# NUC100DN_v1 register map
File version: 1.0
Registers are 32-bit, read-write, reset 0x0 unless marked. A register's access mark holds for its fields unless they carry their own. Offsets are from the block's base; [hi:lo] are bit positions; lines under a group give offsets from that group; {n}, {i} and the like mark numbered series; 'fields as' and 'values as' point back to an identical list.

## PWMA — PWM Register Map
Base 0x40040000
Same registers: PWMB 0x40140000
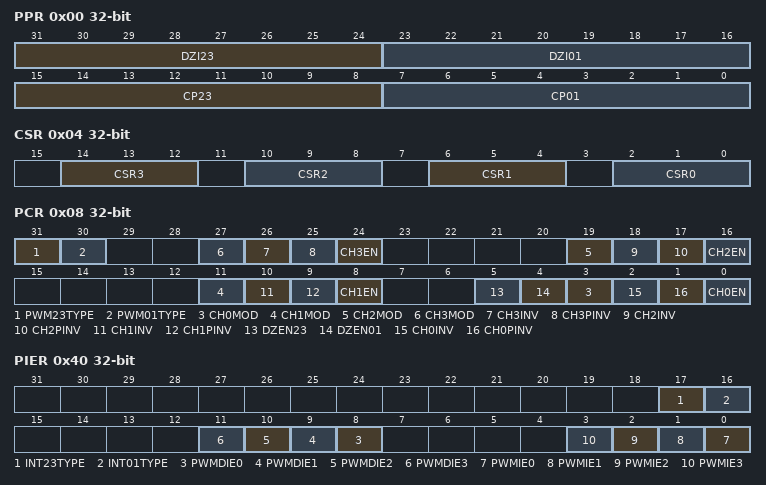
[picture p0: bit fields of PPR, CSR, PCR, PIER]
0x00 PPR — PWM Prescaler Register
  [31:24] DZI23 — Dead-zone Interval for Pair of Channel2 and Channel3 (PWM2 and PWM3 Pair for PWM Group A, PWM6 and PWM7 Pair for PWM Group B). These 8-bit determine the Dead-zone length.
  [23:16] DZI01 — Dead-zone Interval for Pair of Channel 0 and Channel 1 (PWM0 and PWM1 Pair for PWM Group A, PWM4 and PWM5 Pair for PWM Group B). These 8-bit determine the Dead-zone length.
  [15:8] CP23 — Clock Prescaler 2 (PWM-timer2 / 3 for Group a and PWM-timer 6 / 7 for Group B). Clock input is divided by (CP23 + 1) before it is fed to the corresponding PWM-timer
  [7:0] CP01 — Clock Prescaler 0 (PWM-timer 0 / 1 for Group a and PWM-timer 4 / 5 for Group B). Clock input is divided by (CP01 + 1) before it is fed to the corresponding PWM-timer
0x04 CSR — PWM Clock Source Divider Select Register
  [14:12] CSR3 — PWM Timer 3 Clock Source Divider Selection (PWM Timer 3 for Group a and PWM Timer 7 for Group B). Select clock source divider for PWM timer 3.
    0=Input Clock Divided by 2; 1=Input Clock Divided by 4; 2=Input Clock Divided by 8; 3=Input Clock Divided by 16; 4=Input Clock Divided by 1
  [10:8] CSR2 — PWM Timer 2 Clock Source Divider Selection (PWM Timer 2 for Group a and PWM Timer 6 for Group B). Select clock source divider for PWM timer 2. (Table is the same as CSR3)
  [6:4] CSR1 — PWM Timer 1 Clock Source Divider Selection (PWM Timer 1 for Group a and PWM Timer 5 for Group B). Select clock source divider for PWM timer 1. (Table is the same as CSR3)
  [2:0] CSR0 — PWM Timer 0 Clock Source Divider Selection (PWM Timer 0 for Group a and PWM Timer 4 for Group B). Select clock source divider for PWM timer 0. (Table is the same as CSR3)
0x08 PCR — PWM Control Register
  [31] PWM23TYPE — PWM23 Aligned Type Selection Bit (PWM2 and PWM3 Pair for PWM Group A, PWM6 and PWM7 Pair for PWM Group B)
    0=Edge-aligned type; 1=Center-aligned type
  [30] PWM01TYPE — PWM01 Aligned Type Selection Bit (PWM0 and PWM1 Pair for PWM Group A, PWM4 and PWM5 Pair for PWM Group B)
    0=Edge-aligned type; 1=Center-aligned type
  [8n+3] CH{n}MOD (n=0..3) — PWM-timer {n} Auto-reload/One-shot Mode (PWM Timer {n} for Group a and PWM Timer {n+4} for Group B). Note: If there is a transition at this bit, it will cause CNR{n} and CMR{n} be cleared.
    0=One-shot mode; 1=Auto-reload mode
  [26] CH3INV — PWM-timer 3 Output Inverter Enable Bit (PWM Timer 3 for Group a and PWM Timer 7 for Group B)
    0=Inverter Disabled; 1=Inverter Enabled
  [25] CH3PINV — PWM-timer 3 Output Polar Inverse Enable Bit (PWM Timer 3 for Group a and PWM Timer 7 for Group B)
    0=PWM3 output polar inverse Disable; 1=PWM3 output polar inverse Enable
  [24] CH3EN — PWM-timer 3 Enable Bit (PWM Timer 3 for Group a and PWM Timer 7 for Group B)
    0=Corresponding PWM-Timer Stopped; 1=Corresponding PWM-Timer Start Running
  [18] CH2INV — PWM-timer 2 Output Inverter Enable Bit (PWM Timer 2 for Group a and PWM Timer 6 for Group B)
    0=Inverter Disabled; 1=Inverter Enabled
  [17] CH2PINV — PWM-timer 2 Output Polar Inverse Enable Bit (PWM Timer 2 for Group a and PWM Timer 6 for Group B)
    0=PWM2 output polar inverse Disabled; 1=PWM2 output polar inverse Enabled
  [16] CH2EN — PWM-timer 2 Enable Bit (PWM Timer 2 for Group a and PWM Timer 6 for Group B)
    values as CH3EN
  [10] CH1INV — PWM-timer 1 Output Inverter Enable Bit (PWM Timer 1 for Group a and PWM Timer 5 for Group B)
    0=Inverter Disable; 1=Inverter Enable
  [9] CH1PINV — PWM-timer 1 Output Polar Inverse Enable Bit (PWM Timer 1 for Group a and PWM Timer 5 for Group B)
    0=PWM1 output polar inverse Disabled; 1=PWM1 output polar inverse Enabled
  [8] CH1EN — PWM-timer 1 Enable Bit (PWM Timer 1 for Group a and PWM Timer 5 for Group B)
    values as CH3EN
  [5] DZEN23 — Dead-zone 2 Generator Enable Bit (PWM2 and PWM3 Pair for PWM Group A, PWM6 and PWM7 Pair for PWM Group B). Note: When Dead-zone generator is enabled, the pair of PWM2 and PWM3 becomes a complementary pair for PWM group A and the pair of PWM6 and PWM7 becomes a complementary pair for PWM group B.
    0=Dead-zone 2 generator Disabled; 1=Dead-zone 2 generator Enabled
  [4] DZEN01 — Dead-zone 0 Generator Enable Bit (PWM0 and PWM1 Pair for PWM Group A, PWM4 and PWM5 Pair for PWM Group B). Note: When Dead-zone generator is enabled, the pair of PWM0 and PWM1 becomes a complementary pair for PWM group A and the pair of PWM4 and PWM5 becomes a complementary pair for PWM group B.
    0=Dead-zone 0 generator Disabled; 1=Dead-zone 0 generator Enabled
  [2] CH0INV — PWM-timer 0 Output Inverter Enable Bit (PWM Timer 0 for Group a and PWM Timer 4 for Group B)
    0=Inverter Disabled; 1=Inverter Enabled
  [1] CH0PINV — PWM-timer 0 Output Polar Inverse Enable Bit (PWM Timer 0 for Group a and PWM Timer 4 for Group B)
    0=PWM0 output polar inverse Disabled; 1=PWM0 output polar inverse Enabled
  [0] CH0EN — PWM-timer 0 Enable Bit (PWM Timer 0 for Group a and PWM Timer 4 for Group B)
    0=The corresponding PWM-Timer stops running; 1=The corresponding PWM-Timer starts running
{0xC+0xC*i} CNR{i} (i=0..3) — PWM Counter Register {i}
  [15:0] CNRx — PWM Timer Loaded Value. CNR determines the PWM period. Note: Any write to CNR will take effect in next PWM cycle. Note: When PWM operating at Center-aligned type, CNR value should be set between 0x0000 to 0xFFFE. If CNR equal to 0xFFFF, the PWM will work unpredictable. Note: When CNR value is set to 0, PWM output is always high.
{0x10+0xC*i} CMR{i} (i=0..3) — PWM Comparator Register {i}
  [15:0] CMRx — PWM Comparator Register. CMR determines the PWM duty. Note: Any write to CNR will take effect in next PWM cycle.
{0x14+0xC*i} PDR{i} ro (i=0..3) — PWM Data Register {i}
  [15:0] PDRx — PWM Data Register. User can monitor PDR to know the current value in 16-bit counter.
0x3C PBCR — PWM Backward Compatible Register
  [0] BCn — PWM Backward Compatible Register. Refer to the CCR0/CCR2 register bit 6, 7, 22, 23 description. Note: It is recommended that this bit be set to 1 to prevent CFLRIx and CRLRIx from being cleared when writing CCR0/CCR2.
    0=Configure write 0 to clear CFLRI0~3 and CRLRI0~3; 1=Configure write 1 to clear CFLRI0~3 and CRLRI0~3
0x40 PIER — PWM Interrupt Enable Register
  [17] INT23TYPE — PWM23 Interrupt Period Type Selection Bit (PWM2 and PWM3 Pair for PWM Group A, PWM6 and PWM7 Pair for PWM Group B). Note: This bit is effective when PWM in Center-aligned type only.
    0=PWMIFn will be set if PWM counter underflow; 1=PWMIFn will be set if PWM counter matches CNRn register
  [16] INT01TYPE — PWM01 Interrupt Period Type Selection Bit (PWM0 and PWM1 Pair for PWM Group A, PWM4 and PWM5 Pair for PWM Group B). Note: This bit is effective when PWM in Center-aligned type only.
    values as INT23TYPE
  [n+8] PWMDIE{n} (n=0..3) — PWM Channel {n} Duty Interrupt Enable Bit
    0=PWM channel {n} duty interrupt Disabled; 1=PWM channel {n} duty interrupt Enabled
  [n] PWMIE{n} (n=0..3) — PWM Channel {n} Period Interrupt Enable Bit
    0=PWM channel {n} interrupt Disabled; 1=PWM channel {n} interrupt Enabled
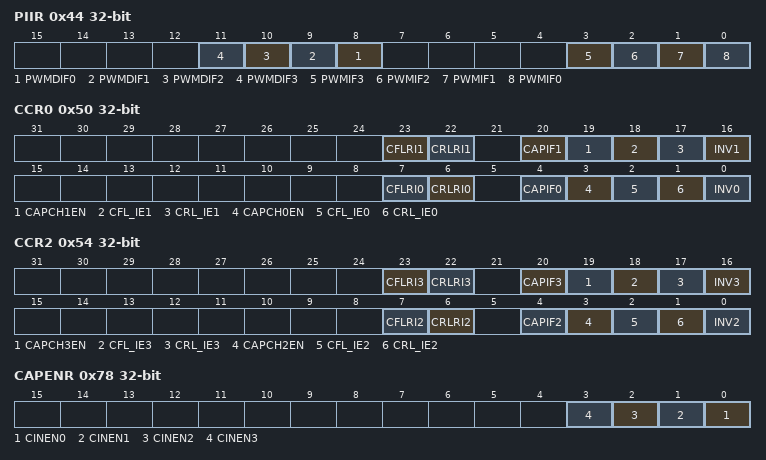
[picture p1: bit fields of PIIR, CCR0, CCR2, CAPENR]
0x44 PIIR — PWM Interrupt Indication Register
  [n+8] PWMDIF{n} (n=0..3) — PWM Channel {n} Duty Interrupt Flag. Flag is set by hardware when channel {n} PWM counter down count and reaches CMR{n}, software can clear this bit by writing a one to it. Note: If CMR equal to CNR, this flag is not working in Edge-aligned type selection
  [3] PWMIF3 — PWM Channel 3 Period Interrupt Status. This bit is set by hardware when PWM3 counter reaches the requirement of interrupt (depend on INT23TYPE bit of PIER register), software can write 1 to clear this bit to 0.
  [2] PWMIF2 — PWM Channel 2 Period Interrupt Status. This bit is set by hardware when PWM2 counter reaches the requirement of interrupt (depend on INT23TYPE bit of PIER register), software can write 1 to clear this bit to 0.
  [1] PWMIF1 — PWM Channel 1 Period Interrupt Status. This bit is set by hardware when PWM1 counter reaches the requirement of interrupt (depend on INT01TYPE bit of PIER register), software can write 1 to clear this bit to 0.
  [0] PWMIF0 — PWM Channel 0 Period Interrupt Status. This bit is set by hardware when PWM0 counter reaches the requirement of interrupt (depend on INT01TYPE bit of PIER register), software can write 1 to clear this bit to 0.
0x50 CCR0 — PWM Capture Control Register 0
  [23] CFLRI1 — CFLR1 Latched Indicator Bit. When PWM group input channel 1 has a falling transition, CFLR1 was latched with the value of PWM down-counter and this bit is set by hardware. Note: Software can write 0 to clear this bit to 0 if BCn bit is 0, and can write 1 to clear this bit to 0 if BCn bit is 1.
  [22] CRLRI1 — CRLR1 Latched Indicator Bit. When PWM group input channel 1 has a rising transition, CRLR1 was latched with the value of PWM down-counter and this bit is set by hardware. Note: Software can write 0 to clear this bit to 0 if BCn bit is 0, and can write 1 to clear this bit to0 if BCn bit is 1.
  [20] CAPIF1 — Channel 1 Capture Interrupt Indication Flag. Note: This bit can be cleared by writing '1' to it.
  [19] CAPCH1EN — Channel 1 Capture Function Enable Bit. When Enabled, Capture latched the PWM-counter and saved to CRLR (Rising latch) and CFLR (Falling latch). When Disabled, Capture does not update CRLR and CFLR, and disable PWM group channel 1 Interrupt.
    0=Capture function on PWM group channel 1 Disabled; 1=Capture function on PWM group channel 1 Enabled
  [18] CFL_IE1 — Channel 1 Falling Latch Interrupt Enable Bit. When Enabled, if Capture detects PWM group channel 1 has falling transition, Capture will issue an Interrupt.
    0=Falling latch interrupt Disabled; 1=Falling latch interrupt Enabled
  [17] CRL_IE1 — Channel 1 Rising Latch Interrupt Enable Bit. When Enabled, if Capture detects PWM group channel 1 has rising transition, Capture will issue an Interrupt.
    0=Rising latch interrupt Disabled; 1=Rising latch interrupt Enabled
  [16] INV1 — Channel 1 Inverter Enable Bit
    0=Inverter Disabled; 1=Inverter Enabled. Reverse the input signal from GPIO before fed to Capture timer
  [7] CFLRI0 — CFLR0 Latched Indicator Bit. When PWM group input channel 0 has a falling transition, CFLR0 was latched with the value of PWM down-counter and this bit is set by hardware. Note: Software can write 0 to clear this bit to 0 if the BCn bit is 0, and can write 1 to clear this bit to0 if BCn bit is 1.
  [6] CRLRI0 — CRLR0 Latched Indicator Bit. When PWM group input channel 0 has a rising transition, CRLR0 was latched with the value of PWM down-counter and this bit is set by hardware. Note: Software can write 0 to clear this bit to 0 if the BCn bit is 0, and can write 1 to clear this bit to 0 if the BCn bit is 1.
  [4] CAPIF0 — Channel 0 Capture Interrupt Indication Flag. Note: This bit can be cleared by writing '1' to it.
  [3] CAPCH0EN — Channel 0 Capture Function Enable Bit. When Enabled, Capture latched the PWM-counter value and saved to CRLR (Rising latch) and CFLR (Falling latch). When Disabled, Capture does not update CRLR and CFLR, and disable PWM group channel 0 Interrupt.
    0=Capture function on PWM group channel 0 Disabled; 1=Capture function on PWM group channel 0 Enabled
  [2] CFL_IE0 — Channel 0 Falling Latch Interrupt Enable. When Enabled, if Capture detects PWM group channel 0 has falling transition, Capture will issue an Interrupt.
    values as CFL_IE1
  [1] CRL_IE0 — Channel 0 Rising Latch Interrupt Enable Bit. When Enabled, if Capture detects PWM group channel 0 has rising transition, Capture will issue an Interrupt.
    values as CRL_IE1
  [0] INV0 — Channel 0 Inverter Enable Bit
    values as INV1
0x54 CCR2 — PWM Capture Control Register 2
  [23] CFLRI3 — CFLR3 Latched Indicator Bit. When PWM group input channel 3 has a falling transition, CFLR3 was latched with the value of PWM down-counter and this bit is set by hardware. Note: Software can write 0 to clear this bit to 0 if the BCn bit is 0, and can write 1 to clear this bit to 0 if the BCn bit is 1.
  [22] CRLRI3 — CRLR3 Latched Indicator Bit. When PWM group input channel 3 has a rising transition, CRLR3 was latched with the value of PWM down-counter and this bit is set by hardware. Note: Software can write 0 to clear this bit to 0 if the BCn bit is 0, and can write 1 to clear this bit to 0 if the BCn bit is 1.
  [20] CAPIF3 — Channel 3 Capture Interrupt Indication Flag. Note: Write 1 to clear this bit to 0
  [19] CAPCH3EN — Channel 3 Capture Function Enable Bit. When Enabled, Capture latched the PWM-counter and saved to CRLR (Rising latch) and CFLR (Falling latch). When Disabled, Capture does not update CRLR and CFLR, and disable PWM group channel 3 Interrupt.
    0=Capture function on PWM group channel 3 Disabled; 1=Capture function on PWM group channel 3 Enabled
  [18] CFL_IE3 — Channel 3 Falling Latch Interrupt Enable Bit. When Enabled, if Capture detects PWM group channel 3 has falling transition, Capture will issue an Interrupt.
    values as CCR0.CFL_IE1
  [17] CRL_IE3 — Channel 3 Rising Latch Interrupt Enable Bit. When Enabled, if Capture detects PWM group channel 3 has rising transition, Capture will issue an Interrupt.
    values as CCR0.CRL_IE1
  [16] INV3 — Channel 3 Inverter Enable Bit
    values as CCR0.INV1
  [7] CFLRI2 — CFLR2 Latched Indicator Bit. When PWM group input channel 2 has a falling transition, CFLR2 was latched with the value of PWM down-counter and this bit is set by hardware. Note: Software can write 0 to clear this bit to 0 if BCn bit is 0, and can write 1 to clear this bit to 0 if the BCn bit is 1.
  [6] CRLRI2 — CRLR2 Latched Indicator Bit. When PWM group input channel 2 has a rising transition, CRLR2 was latched with the value of PWM down-counter and this bit is set by hardware. Note: Software can write 0 to clear this bit to 0 if the BCn bit is 0, and can write 1 to clear this bit to 0 if the BCn bit is 1.
  [4] CAPIF2 — Channel 2 Capture Interrupt Indication Flag. Note: Write 1 to clear this bit to 0
  [3] CAPCH2EN — Channel 2 Capture Function Enable Bit. When Enabled, Capture latched the PWM-counter value and saved to CRLR (Rising latch) and CFLR (Falling latch). When Disabled, Capture does not update CRLR and CFLR, and disable PWM group channel 2 Interrupt.
    0=Capture function on PWM group channel 2 Disabled; 1=Capture function on PWM group channel 2 Enabled
  [2] CFL_IE2 — Channel 2 Falling Latch Interrupt Enable Bit. When Enabled, if Capture detects PWM group channel 2 has falling transition, Capture will issue an Interrupt.
    values as CCR0.CFL_IE1
  [1] CRL_IE2 — Channel 2 Rising Latch Interrupt Enable Bit. When Enabled, if Capture detects PWM group channel 2 has rising transition, Capture will issue an Interrupt.
    values as CCR0.CRL_IE1
  [0] INV2 — Channel 2 Inverter Enable Bit
    values as CCR0.INV1
{0x58+8i} CRLR{i} ro (i=0..3) — PWM Capture Rising Latch Register (Channel {i})
  [15:0] CRLRx — Capture Rising Latch Register. Latch the PWM counter when Channel 0/1/2/3 has rising transition.
{0x5C+8i} CFLR{i} ro (i=0..3) — PWM Capture Falling Latch Register (Channel {i})
  [15:0] CFLRx — Capture Falling Latch Register. Latch the PWM counter when Channel 0/1/2/3 has Falling transition.
0x78 CAPENR — PWM Capture Input 0~3 Enable Register
  [n] CINEN{n} (n=0..3) — Channel {n} Capture Input Enable Bit
    0=PWM Channel {n} capture input path Disabled. The input of PWM channel {n} capture function is always regarded as 0; 1=PWM Channel {n} capture input path Enabled. The input of PWM channel {n} capture function comes from correlative multifunction pin if GPIO multi-function is set as PWM{n}
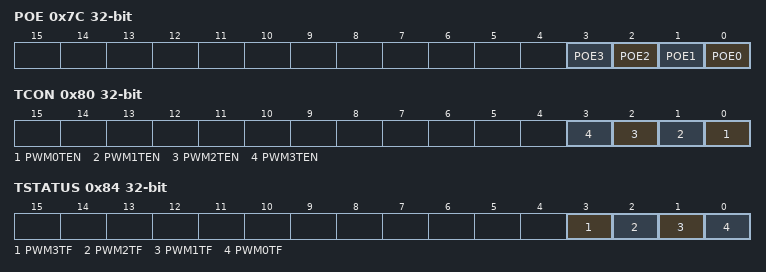
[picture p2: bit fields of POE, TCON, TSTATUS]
0x7C POE — PWM Output Enable for Channel 0~3
  [n] POE{n} (n=0..3) — Channel {n} Output Enable Bit. Note: The corresponding GPIO pin must also be switched to PWM function
    0=PWM channel {n} output to pin Disabled; 1=PWM channel {n} output to pin Enabled
0x80 TCON — PWM Trigger Control for Channel 0~3
  [n] PWM{n}TEN (n=0..3) — Channel {n} Center-aligned Trigger Enable Bit. PWM can trigger ADC to start conversion when PWM counter up count to CNR if this bit is set to 1. Note: This function is only supported when PWM operating at Center-aligned type.
    0=PWM channel {n} trigger ADC function Disabled; 1=PWM channel {n} trigger ADC function Enabled
0x84 TSTATUS — PWM Trigger Status Register
  [3] PWM3TF — Channel 3 Center-aligned Trigger Flag. For Center-aligned Operating mode, this bit is set to 1 by hardware when PWM counter up count to CNR if PWM3TEN bit is set to 1. After this bit is set to 1, ADC will start conversion if ADC triggered source is selected by PWM. Note: This bit can be cleared by writing '1' to it.
  [2] PWM2TF — Channel 2 Center-aligned Trigger Flag. For Center-aligned Operating mode, this bit is set to 1 by hardware when PWM counter up count to CNR if PWM2TEN bit is set to 1. After this bit is set to 1, ADC will start conversion if ADC triggered source is selected by PWM. Note: This bit can be cleared by writing '1' to it.
  [1] PWM1TF — Channel 1 Center-aligned Trigger Flag. For Center-aligned Operating mode, this bit is set to 1 by hardware when PWM counter up count to CNR if PWM1TEN bit is set to 1. After this bit is set to 1, ADC will start conversion if ADC triggered source is selected by PWM. Note: This bit can be cleared by writing '1' to it.
  [0] PWM0TF — Channel 0 Center-aligned Trigger Flag. For Center-aligned Operating mode, this bit is set to 1 by hardware when PWM counter up counts to CNR if PWM0TEN bit is set to 1. After this bit is set to 1, ADC will start conversion if ADC triggered source is selected by PWM. Note: This bit can be cleared by writing '1' to it.
0x88 SYNCBUSY0 ro — PWM0 Synchronous Busy Status Register
  [0] S_BUSY — PWM Synchronous Busy. When software writes CNR0/CMR0/PPR or switches PWM0 operation mode (PCR[3]), PWM will have a busy time to update these values completely because PWM clock may be different from system clock domain. SOFTWARE needs to check this busy status before writing CNR0/CMR0/PPR or switching PWM0 operation mode (PCR[3]) to make sure previous setting has been updated completely. This bit will be set when software writes CNR0/CMR0/PPR or switches PWM0 operation mode (PCR[3]) and will be cleared by hardware automatically when PWM update these value completely.
0x8C SYNCBUSY1 ro — PWM1 Synchronous Busy Status Register
  [0] S_BUSY — PWM Synchronous Busy. When software writes CNR1/CMR1/PPR or switches PWM1 operation mode (PCR[11]), PWM will have a busy time to update these values completely because PWM clock may be different from system clock domain. Software needs to check this busy status before writing CNR1/CMR1/PPR or switching PWM1 operation mode (PCR[11]) to make sure previous setting has been updated completely. This bit will be set when software writes CNR1/CMR1/PPR or switches PWM1 operation mode (PCR[11]) and will be cleared by hardware automatically when PWM update these value completely.
0x90 SYNCBUSY2 ro — PWM2 Synchronous Busy Status Register
  [0] S_BUSY — PWM Synchronous Busy. When software writes CNR2/CMR2/PPR or switch PWM2 operation mode (PCR[19]), PWM will have a busy time to update these values completely because PWM clock may be different from system clock domain. Software needs to check this busy status before writing CNR2/CMR2/PPR or switching PWM2 operation mode (PCR[19]) to make sure previous setting has been updated completely. This bit will be set when software writes CNR2/CMR2/PPR or switch PWM2 operation mode (PCR[19]) and will be cleared by hardware automatically when PWM update these value completely.
0x94 SYNCBUSY3 ro — PWM3 Synchronous Busy Status Register
  [0] S_BUSY — PWM Synchronous Busy. When software writes CNR3/CMR3/PPR or switch PWM3 operation mode (PCR[27]), PWM will have a busy time to update these values completely because PWM clock may be different from system clock domain. Software need to check this busy status before writing CNR3/CMR3/PPR or switching PWM3 operation mode (PCR[27]) to make sure previous setting has been updated completely. This bit will be set when software writes CNR3/CMR3/PPR or switch PWM3 operation mode (PCR[27]) and will be cleared by hardware automatically when PWM update these value completely.
